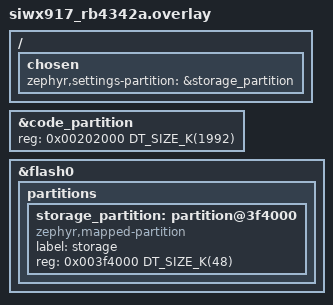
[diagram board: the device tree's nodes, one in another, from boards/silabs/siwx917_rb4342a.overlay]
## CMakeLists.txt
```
#
#    Copyright (c) 2026 Project CHIP Authors
#
#    Licensed under the Apache License, Version 2.0 (the "License");
#    you may not use this file except in compliance with the License.
#    You may obtain a copy of the License at
#
#        http://www.apache.org/licenses/LICENSE-2.0
#
#    Unless required by applicable law or agreed to in writing, software
#    distributed under the License is distributed on an "AS IS" BASIS,
#    WITHOUT WARRANTIES OR CONDITIONS OF ANY KIND, either express or implied.
#    See the License for the specific language governing permissions and
#    limitations under the License.
#
cmake_minimum_required(VERSION 3.20)

# You may point this at a header that defines chip::app::AllDevices::AppTask as the
# final type of a CRTP layer chain rooted at AppTaskBase (see include/AppTask.h).
if(NOT DEFINED APP_TASK_IMPL_HEADER)
    set(APP_TASK_IMPL_HEADER "")
endif()

# Zephyr auto-discovers files directly under boards/. This also discovers
# board files in the registered vendor subdirectories.
include(${CMAKE_CURRENT_SOURCE_DIR}/cmake/board_files.cmake)
if(DEFINED BOARD)
    all_devices_board_name(${BOARD} ALL_DEVICES_BOARD_NAME)

    if(NOT SYSBUILD)
        all_devices_find_board_file(${CMAKE_CURRENT_SOURCE_DIR}/boards ${ALL_DEVICES_BOARD_NAME}.overlay
                                     ALL_DEVICES_NESTED_BOARD_OVERLAY EXCLUDE_FLAT)
        if(ALL_DEVICES_NESTED_BOARD_OVERLAY)
            list(APPEND DTC_OVERLAY_FILE ${ALL_DEVICES_NESTED_BOARD_OVERLAY})
            set(DTC_OVERLAY_FILE "${DTC_OVERLAY_FILE}" CACHE STRING "Application devicetree overlays" FORCE)
        endif()
    else()
        all_devices_find_board_file(${CMAKE_CURRENT_SOURCE_DIR}/boards ${ALL_DEVICES_BOARD_NAME}.overlay
                                     ALL_DEVICES_NESTED_BOARD_OVERLAY EXCLUDE_FLAT)
        list(REMOVE_ITEM DTC_OVERLAY_FILE ${ALL_DEVICES_NESTED_BOARD_OVERLAY})
        set(DTC_OVERLAY_FILE "${DTC_OVERLAY_FILE}" CACHE STRING "Application devicetree overlays" FORCE)
    endif()
    message(VERBOSE "BOARD=${BOARD} ALL_DEVICES_BOARD_NAME=${ALL_DEVICES_BOARD_NAME} ALL_DEVICES_NESTED_BOARD_OVERLAY=${ALL_DEVICES_NESTED_BOARD_OVERLAY} EXTRA_DTC_OVERLAY_FILE=${EXTRA_DTC_OVERLAY_FILE}")

    all_devices_find_board_file(${CMAKE_CURRENT_SOURCE_DIR}/boards ${ALL_DEVICES_BOARD_NAME}.conf
                                 ALL_DEVICES_NESTED_BOARD_CONF EXCLUDE_FLAT)
    if(ALL_DEVICES_NESTED_BOARD_CONF)
        list(APPEND EXTRA_CONF_FILE ${ALL_DEVICES_NESTED_BOARD_CONF})
    endif()

endif()

find_package(Zephyr HINTS $ENV{ZEPHYR_BASE})

# Matter is the Zephyr module "connectedhomeip"; it must be in the west manifest.
if(NOT DEFINED ZEPHYR_CONNECTEDHOMEIP_MODULE_DIR)
    message(FATAL_ERROR "Matter is not registered as a Zephyr module. Add it to your west manifest.")
endif()
set(CHIP_ROOT ${ZEPHYR_CONNECTEDHOMEIP_MODULE_DIR})
set(ALL_DEVICES_COMMON_DIR ${CHIP_ROOT}/examples/all-devices-app/all-devices-common)

# Device selection comes from Kconfig (CONFIG_ALL_DEVICES_DEVICE_*, see Kconfig.devices).
# -DALL_DEVICES_ENABLED_DEVICES="on-off-light;..." overrides it; an empty list means all devices.
if(NOT DEFINED ALL_DEVICES_ENABLED_DEVICES)
    set(ALL_DEVICES_ENABLED_DEVICES "")
    get_cmake_property(_all_devices_vars VARIABLES)
    foreach(_var IN LISTS _all_devices_vars)
        if(_var MATCHES "^CONFIG_ALL_DEVICES_DEVICE_(.+)$" AND ${_var})
            string(TOLOWER "${CMAKE_MATCH_1}" _key)
            string(REPLACE "_" "-" _key "${_key}")
            list(APPEND ALL_DEVICES_ENABLED_DEVICES "${_key}")
        endif()
    endforeach()
endif()
include(${ALL_DEVICES_COMMON_DIR}/device-factory/enabled_devices.cmake)

# Count enabled device keys to size AppTask's device array. 
get_cmake_property(_all_devices_vars VARIABLES)
set(ALL_DEVICES_ENABLED_DEVICE_COUNT 0)
foreach(_var IN LISTS _all_devices_vars)
    if(_var MATCHES "^ALL_DEVICES_ENABLE_" AND ${_var})
        math(EXPR ALL_DEVICES_ENABLED_DEVICE_COUNT "${ALL_DEVICES_ENABLED_DEVICE_COUNT} + 1")
    endif()
endforeach()

#Some keys register more than one creator, so include those additional creators as well.
foreach(_variant_key FAN OVEN REFRIGERATOR)
    if(ALL_DEVICES_ENABLE_${_variant_key})
        math(EXPR ALL_DEVICES_ENABLED_DEVICE_COUNT "${ALL_DEVICES_ENABLED_DEVICE_COUNT} + 1")
    endif()
endforeach()

# ot-config re-lists zephyr_interface's INTERFACE_COMPILE_DEFINITIONS, including
# $<COMPILE_LANGUAGE:CXX> generator expressions. openthread/CMakeLists.txt uses
# ot-config's defines to build a plain custom target, where COMPILE_LANGUAGE is
# invalid. Strip it so LLVM/Clang builds configure cleanly.
if(CONFIG_OPENTHREAD AND TARGET ot-config AND TARGET zephyr_interface)
    get_target_property(OT_CONFIG_DEFS ot-config INTERFACE_COMPILE_DEFINITIONS)
    if(OT_CONFIG_DEFS)
        list(FILTER OT_CONFIG_DEFS EXCLUDE REGEX "TARGET_PROPERTY:zephyr_interface,INTERFACE_COMPILE_DEFINITIONS")
    else()
        set(OT_CONFIG_DEFS "")
    endif()
    get_target_property(ZEPHYR_INTERFACE_DEFS zephyr_interface INTERFACE_COMPILE_DEFINITIONS)
    if(ZEPHYR_INTERFACE_DEFS)
        list(FILTER ZEPHYR_INTERFACE_DEFS EXCLUDE REGEX "COMPILE_LANGUAGE:CXX")
    else()
        set(ZEPHYR_INTERFACE_DEFS "")
    endif()
    set_target_properties(ot-config PROPERTIES
        INTERFACE_COMPILE_DEFINITIONS "${OT_CONFIG_DEFS};${ZEPHYR_INTERFACE_DEFS}")
endif()

project(matter-all-devices-zephyr)

include(${CHIP_ROOT}/src/app/chip_data_model.cmake)

# Silabs extension point
include(${CMAKE_CURRENT_SOURCE_DIR}/silabs/CMakeLists.txt)

target_compile_options(app PRIVATE -Werror -Wno-error=format)
if(CMAKE_C_COMPILER_ID STREQUAL "GNU")
    target_compile_options(app PRIVATE -Werror -Wno-error=maybe-uninitialized)
endif()

target_compile_definitions(app PRIVATE ALL_DEVICES_ENABLED_DEVICE_COUNT=${ALL_DEVICES_ENABLED_DEVICE_COUNT})

if(NOT APP_TASK_IMPL_HEADER STREQUAL "")
    target_compile_definitions(app PRIVATE APP_TASK_IMPL_HEADER="${APP_TASK_IMPL_HEADER}")
endif()

target_include_directories(app PRIVATE
    ${CMAKE_CURRENT_SOURCE_DIR}
    src
    include
    ${ALL_DEVICES_COMMON_DIR}
    ${CMAKE_CURRENT_BINARY_DIR} # for generated app_config/enabled_devices.h
)

target_sources(app PRIVATE
    CHIPProjectConfig.h
    include/AppTaskBase.h
    include/AppTaskBase.ipp
    include/AppTask.h
    include/Buttons.h
    src/Buttons.cpp
    src/main.cpp

    # Identify
    include/delegates/ZephyrIdentifyDelegate.h
    src/delegates/ZephyrIdentifyDelegate.cpp

    # all-devices-common
    ${ALL_DEVICES_DEVICE_SOURCES}
    ${ALL_DEVICES_CLUSTER_SOURCES}
)

# Included by AppTaskBase.h; listed above only so it shows up in IDEs.
set_source_files_properties(include/AppTaskBase.ipp PROPERTIES HEADER_FILE_ONLY TRUE)

# Board-specific device implementation; AppTaskBase substitutes it into the factory.
if(ALL_DEVICES_ENABLE_ON_OFF_LIGHT)
    target_sources(app PRIVATE
        include/devices/ZephyrOnOffLight.h
        src/devices/ZephyrOnOffLight.cpp
    )
endif()

# Matches CHIP_DEVICE_CONFIG_ENABLE_THREAD, which AppTaskBase.ipp gates on.
if(CONFIG_OPENTHREAD)
    target_sources(app PRIVATE
        ${ALL_DEVICES_COMMON_DIR}/device/types/root-node/features/ThreadFeature.cpp
        )
endif()

if(CONFIG_CHIP_WIFI)
    target_sources(app PRIVATE
        ${ALL_DEVICES_COMMON_DIR}/device/types/root-node/features/WifiFeature.cpp
    )
endif()

if(CONFIG_CHIP_OTA_REQUESTOR)
    target_sources(app PRIVATE
        ${ALL_DEVICES_COMMON_DIR}/device/types/root-node/features/OtaFeature.cpp
        ${CHIP_ROOT}/src/app/clusters/ota-requestor/BDXDownloader.cpp
        ${CHIP_ROOT}/src/app/clusters/ota-requestor/DefaultOTARequestor.cpp
        ${CHIP_ROOT}/src/app/clusters/ota-requestor/DefaultOTARequestorDriver.cpp
        ${CHIP_ROOT}/src/app/clusters/ota-requestor/DefaultOTARequestorStorage.cpp
        ${CHIP_ROOT}/src/app/clusters/ota-requestor/ExtendedOTARequestorDriver.cpp
        ${CHIP_ROOT}/src/app/clusters/ota-requestor/OTATestEventTriggerHandler.cpp
        ${CHIP_ROOT}/src/app/clusters/ota-requestor/OTARequestorAttributes.cpp
        ${CHIP_ROOT}/src/app/clusters/ota-requestor/OTARequestorCluster.cpp
    )

    if(CONFIG_MCUBOOT_SIGNATURE_KEY_FILE STREQUAL "")
        set(ALL_DEVICES_OTA_BASE_NAME "zephyr")
    else()
        set(ALL_DEVICES_OTA_BASE_NAME "zephyr.signed")
    endif()

    if(CONFIG_CHIP_OTA_IMAGE_BUILD)
        chip_zephyr_ota_image(chip-ota-image
            INPUT_FILES ${PROJECT_BINARY_DIR}/zephyr/${ALL_DEVICES_OTA_BASE_NAME}.bin
            OUTPUT_FILE ${PROJECT_BINARY_DIR}/zephyr/${CONFIG_CHIP_OTA_IMAGE_FILE_NAME}
        )
    endif()
endif()
```

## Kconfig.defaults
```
#
# Copyright (c) 2026 Project CHIP Authors
#
# Licensed under the Apache License, Version 2.0 (the "License");
# you may not use this file except in compliance with the License.
# You may obtain a copy of the License at
#
# http://www.apache.org/licenses/LICENSE-2.0
#
# Unless required by applicable law or agreed to in writing, software
# distributed under the License is distributed on an "AS IS" BASIS,
# WITHOUT WARRANTIES OR CONDITIONS OF ANY KIND, either express or implied.
# See the License for the specific language governing permissions and
# limitations under the License.
#

DT_CHOSEN_IEEE802154 := zephyr,ieee802154

if CHIP

# Only enable the OpenThread L2 on boards that expose a 802.15.4 radio.
config NET_L2_OPENTHREAD
	default y if $(dt_chosen_enabled,$(DT_CHOSEN_IEEE802154))
	default n

choice STD_CPP
	default STD_CPP17
endchoice

config CHIP_ENABLE_PAIRING_AUTOSTART
	default y

# The app builds its data model at run time.
config CHIP_DATA_MODEL_CODEDRIVEN
	default y

config CHIP_ENABLE_GROUPCAST
	default y

config CHIP_PERSISTENT_SUBSCRIPTIONS
	default y

config CHIP_OTA_REQUESTOR
	default n

config IMG_MANAGER
	default y if CHIP_OTA_BACKEND_MCUBOOT

config STREAM_FLASH
	default n

config STREAM_FLASH_ERASE
	default n

config BOOTLOADER_MCUBOOT
	default y if CHIP_OTA_BACKEND_MCUBOOT

config CHIP_OTA_BACKEND_MCUBOOT
	imply STREAM_FLASH
	imply STREAM_FLASH_ERASE

config BT
	default y

config BT_PERIPHERAL
	default y

config BT_DEVICE_NAME
	default "MatterAllDev"

config BT_HOST_CRYPTO
	default y

config MBEDTLS_ENTROPY_C
	default y

config MBEDTLS_PSA_DRIVER_GET_ENTROPY
	default y

config LOG
	default y

choice LOG_MODE
	default LOG_MODE_DEFERRED
endchoice

config SYSTEM_WORKQUEUE_STACK_SIZE
	default 4096

config THREAD_LOCAL_STORAGE
	default y

config MAIN_STACK_SIZE
	default 12288

config CHIP_TASK_STACK_SIZE
	default 10240

config HW_STACK_PROTECTION
	default y

config ASSERT
	default y

if NET_L2_OPENTHREAD

config NET_IF_MCAST_IPV6_ADDR_COUNT
	default 14

config OPENTHREAD_THREAD_STACK_SIZE
	default 6144

endif # NET_L2_OPENTHREAD

choice POSIX_AEP_CHOICE
	default POSIX_AEP_CHOICE_NONE
endchoice

config MBEDTLS
	default y

choice CHIP_CRYPTO
	default CHIP_CRYPTO_PSA
endchoice

config MBEDTLS_HEAP_SIZE
	default 8192

# CHIPCryptoPALPSA.cpp uses mbedtls_md_info_from_type() for SPAKE2+.
config MBEDTLS_MD_C
	default y if CHIP_CRYPTO_SPAKE2P_MBEDTLS

# Extend the maximum number of PSA key slots to fit Matter requirements
config MBEDTLS_PSA_KEY_SLOT_COUNT
	default 64

config CHIP_FACTORY_DATA
	bool "Use provisioned factory data for credentials and commissionable data"
	default n

config SHELL
	default y

config CHIP_LIB_SHELL
	default y

config CHIP_WIFI
	default y if WIFI
	imply NET_STATISTICS
	imply NET_IPV6_ND
	imply NET_IPV6_NBR_CACHE
	imply NET_STATISTICS_IPV6
	imply NET_STATISTICS_USER_API

config CHIP_ENABLE_WIFI_STATION
	default y if CHIP_WIFI

if CHIP_WIFI
config NET_IF_IPV6_PREFIX_COUNT
	default NET_IF_UNICAST_IPV6_ADDR_COUNT
config NET_BUF_DATA_SIZE
	default 512
endif

if SHELL

config SHELL_STACK_SIZE
    default 2616 if CHIP_WIFI

config SHELL_MINIMAL
    default y

config KERNEL_SHELL
    default n

config SHELL_WILDCARD
	default n

config SENSOR_SHELL
    default n

config DEVICE_SHELL
    default n

config DATE_SHELL
    default n

config DEVMEM_SHELL
    default n

config MCUBOOT_SHELL
    default n

config CLOCK_CONTROL_NRF_SHELL
    default n

config FLASH_SHELL
    default n

config HWINFO_SHELL
    default n

endif # SHELL

# Silabs optimizations
if SOC_FAMILY_SILABS_S2 && $(dt_chosen_enabled,$(DT_CHOSEN_IEEE802154))

# OpenThread L2 still needs Zephyr networking without Matter socket endpoints.
config NETWORKING
	default y

config CHIP_USE_ZEPHYR_NETWORKING
	default n

if NET_L2_OPENTHREAD

config CHIP_USE_OT_ENDPOINT
	default !CHIP_USE_ZEPHYR_NETWORKING

config NET_IPV6_NBR_CACHE
	default n if CHIP_USE_OT_ENDPOINT

config NET_PKT_RX_COUNT
	default 8

config NET_PKT_TX_COUNT
	default 8

config NET_BUF_RX_COUNT
	default 16

config NET_BUF_TX_COUNT
	default 16

config OPENTHREAD_NUM_MESSAGE_BUFFERS
	default 64

if CHIP_CRYPTO_PSA

choice OPENTHREAD_SECURITY_CONFIG
	default OPENTHREAD_SECURITY_CUSTOM_CONFIG
endchoice

# Custom Thread security does not imply PSA persistent-key storage.
config SECURE_STORAGE
	default y if !BUILD_WITH_TFM

config PSA_WANT_KEY_TYPE_HMAC
	default y

config PSA_WANT_KEY_TYPE_ECC_KEY_PAIR_IMPORT
	default y

config PSA_WANT_KEY_TYPE_ECC_KEY_PAIR_EXPORT
	default y

config PSA_WANT_ALG_DETERMINISTIC_ECDSA
	default y

config MBEDTLS_ASN1_PARSE_C
	default y

config CHIP_CRYPTO_PSA_AEAD_SINGLE_PART
	default y

endif # CHIP_CRYPTO_PSA

if MCUBOOT_IMG_MANAGER

config IMG_ERASE_PROGRESSIVELY
	default y

endif # MCUBOOT_IMG_MANAGER

endif # NET_L2_OPENTHREAD

endif # SOC_FAMILY_SILABS_S2 && DT_CHOSEN_IEEE802154

endif # CHIP
```

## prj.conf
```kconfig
#
#    Copyright (c) 2026 Project CHIP Authors
#
#    Licensed under the Apache License, Version 2.0 (the "License");
#    you may not use this file except in compliance with the License.
#    You may obtain a copy of the License at
#
#        http://www.apache.org/licenses/LICENSE-2.0
#
#    Unless required by applicable law or agreed to in writing, software
#    distributed under the License is distributed on an "AS IS" BASIS,
#    WITHOUT WARRANTIES OR CONDITIONS OF ANY KIND, either express or implied.
#    See the License for the specific language governing permissions and
#    limitations under the License.
#

CONFIG_CHIP=y
CONFIG_LOG_DEFAULT_LEVEL=3
CONFIG_CHIP_PROJECT_CONFIG="CHIPProjectConfig.h"
CONFIG_OPENTHREAD_SHELL=n

CONFIG_BUILD_OUTPUT_HEX=y
CONFIG_LOG_BUFFER_SIZE=6144

CONFIG_BT_GATT_CACHING=n
```

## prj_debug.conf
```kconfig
#
#    Copyright (c) 2026 Project CHIP Authors
#
#    Licensed under the Apache License, Version 2.0 (the "License");
#    you may not use this file except in compliance with the License.
#    You may obtain a copy of the License at
#
#        http://www.apache.org/licenses/LICENSE-2.0
#
#    Unless required by applicable law or agreed to in writing, software
#    distributed under the License is distributed on an "AS IS" BASIS,
#    WITHOUT WARRANTIES OR CONDITIONS OF ANY KIND, either express or implied.
#    See the License for the specific language governing permissions and
#    limitations under the License.
#

# west build ... -- -DFILE_SUFFIX=debug

CONFIG_CHIP=y
CONFIG_CHIP_PROJECT_CONFIG="CHIPProjectConfig.h"

# Thread introspection: names threads and lists them via the "kernel threads"
# shell command.
CONFIG_THREAD_NAME=y
CONFIG_THREAD_MONITOR=y

# Zero-fills thread stacks at creation and checks a canary word on each
# context switch, so stack overflows/high-water-marks can be diagnosed.
CONFIG_INIT_STACKS=y
CONFIG_STACK_SENTINEL=y

# Verbose application + Matter stack logging.
CONFIG_LOG_DEFAULT_LEVEL=4
CONFIG_CHIP_APP_LOG_LEVEL=4
CONFIG_LOG_INFO_COLOR_GREEN=y
CONFIG_LOG_DBG_COLOR_BLUE=y

# OTA Requestor (MCUboot stream flash / image manager come from Kconfig.defaults)
CONFIG_CHIP_OTA_REQUESTOR=y

# Full __ASSERT() checking (adds spinlock validation and per-assert file info).
CONFIG_ASSERT=y
CONFIG_HW_STACK_PROTECTION=y

CONFIG_SHELL=y
CONFIG_CHIP_LIB_SHELL=y

CONFIG_CONSOLE=y
CONFIG_UART_CONSOLE=y
CONFIG_SERIAL=y
CONFIG_LOG=y
CONFIG_PRINTK=y
CONFIG_PRINTK_SYNC=n
CONFIG_BOOT_BANNER=y

CONFIG_BT_GATT_CACHING=n
```

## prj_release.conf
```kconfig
#
#    Copyright (c) 2026 Project CHIP Authors
#
#    Licensed under the Apache License, Version 2.0 (the "License");
#    you may not use this file except in compliance with the License.
#    You may obtain a copy of the License at
#
#        http://www.apache.org/licenses/LICENSE-2.0
#
#    Unless required by applicable law or agreed to in writing, software
#    distributed under the License is distributed on an "AS IS" BASIS,
#    WITHOUT WARRANTIES OR CONDITIONS OF ANY KIND, either express or implied.
#    See the License for the specific language governing permissions and
#    limitations under the License.
#

# west build ... -- -DFILE_SUFFIX=release

CONFIG_CHIP=y
CONFIG_CHIP_PROJECT_CONFIG="CHIPProjectConfig.h"

CONFIG_USE_SEGGER_RTT=n

# No shell (Matter or OT) in a release build.
CONFIG_SHELL=n
CONFIG_CHIP_LIB_SHELL=n

# No console/log output path at all.
CONFIG_CONSOLE=n
CONFIG_UART_CONSOLE=n
CONFIG_SERIAL=n
CONFIG_LOG=n
CONFIG_PRINTK=n
CONFIG_PRINTK_SYNC=n
CONFIG_BOOT_BANNER=n
CONFIG_MATTER_LOG_LEVEL=0
CONFIG_CHIP_APP_LOG_LEVEL=0

# Development aids
CONFIG_ASSERT=n

# Use Factory Data
# Requires providing a custom implementation
CONFIG_CHIP_FACTORY_DATA=y

# OTA
CONFIG_CHIP_OTA_REQUESTOR=y
CONFIG_CHIP_OTA_IMAGE_BUILD=y
CONFIG_CHIP_DEVICE_SOFTWARE_VERSION=1
CONFIG_CHIP_DEVICE_SOFTWARE_VERSION_STRING="1.0"
CONFIG_MCUBOOT_IMGTOOL_SIGN_VERSION="1.0.0+0"

# LTO
CONFIG_ISR_TABLES_LOCAL_DECLARATION=y
CONFIG_LTO=y
CONFIG_LTO_SINGLE_THREADED=y

CONFIG_BT_GATT_CACHING=n

CONFIG_CBPRINTF_FP_SUPPORT=n
```

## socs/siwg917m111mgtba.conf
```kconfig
#
#    Copyright (c) 2026 Project CHIP Authors
#    All rights reserved.
#
#    Licensed under the Apache License, Version 2.0 (the "License");
#    you may not use this file except in compliance with the License.
#    You may obtain a copy of the License at
#
#        http://www.apache.org/licenses/LICENSE-2.0
#
#    Unless required by applicable law or agreed to in writing, software
#    distributed under the License is distributed on an "AS IS" BASIS,
#    WITHOUT WARRANTIES OR CONDITIONS OF ANY KIND, either express or implied.
#    See the License for the specific language governing permissions and
#    limitations under the License.
#

CONFIG_NVS_LOOKUP_CACHE=y
CONFIG_NVS_LOOKUP_CACHE_SIZE=1024

CONFIG_SETTINGS_NVS_SECTOR_COUNT=12

# Si917 Wi-Fi / Matter-over-Wi-Fi integration.  Keep these explicit instead of
# relying solely on the generic defaults in Kconfig.defaults: CONFIG_WIFI makes
# CHIP_WIFI available, and the latter two select the Matter Wi-Fi root feature
# (Network Commissioning + Wi-Fi Network Diagnostics) and station driver.
CONFIG_WIFI=y
CONFIG_CHIP_WIFI=y
CONFIG_CHIP_ENABLE_WIFI_STATION=y
CONFIG_COMMON_LIBC_MALLOC_ARENA_SIZE=-1

CONFIG_GPIO=y

CONFIG_NET_IF_UNICAST_IPV6_ADDR_COUNT=6
CONFIG_NET_IF_MCAST_IPV6_ADDR_COUNT=14

CONFIG_LOG_BUFFER_SIZE=8192

CONFIG_MBEDTLS_ECP_NIST_OPTIM=y
```

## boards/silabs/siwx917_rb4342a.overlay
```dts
/*
 * Copyright (c) 2026 Project CHIP Authors
 *
 * Licensed under the Apache License, Version 2.0 (the "License");
 * you may not use this file except in compliance with the License.
 * You may obtain a copy of the License at
 *
 *     http://www.apache.org/licenses/LICENSE-2.0
 *
 * Unless required by applicable law or agreed to in writing, software
 * distributed under the License is distributed on an "AS IS" BASIS
 * WITHOUT WARRANTIES OR CONDITIONS OF ANY KIND, either express or implied.
 * See the License for the specific language governing permissions and
 * limitations under the License.
 */

/delete-node/ &storage_partition;

/ {
	chosen {
		zephyr,settings-partition = &storage_partition;
	};
};

&code_partition {
	reg = <0x00202000 DT_SIZE_K(1992)>;
};

&flash0 {
	partitions {
		storage_partition: partition@3f4000 {
			compatible = "zephyr,mapped-partition";
			label = "storage";
			reg = <0x003f4000 DT_SIZE_K(48)>;
		};
	};
};
```

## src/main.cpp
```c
/*
 *
 *    Copyright (c) 2026 Project CHIP Authors
 *    All rights reserved.
 *
 *    Licensed under the Apache License, Version 2.0 (the "License");
 *    you may not use this file except in compliance with the License.
 *    You may obtain a copy of the License at
 *
 *        http://www.apache.org/licenses/LICENSE-2.0
 *
 *    Unless required by applicable law or agreed to in writing, software
 *    distributed under the License is distributed on an "AS IS" BASIS,
 *    WITHOUT WARRANTIES OR CONDITIONS OF ANY KIND, either express or implied.
 *    See the License for the specific language governing permissions and
 *    limitations under the License.
 */

#include "AppTask.h"

#include <lib/core/CHIPError.h>
#include <zephyr/kernel.h>

void RegisterNamedPipeTranslators(DimmableLight & device, NamedPipe::Dispatcher & dispatcher)
{
    const CHIP_ERROR err = chip::app::AllDevices::GetAppTask().Run();
    if (err != CHIP_NO_ERROR)
    {
        printk("AppTask::Run() failed: %" CHIP_ERROR_FORMAT "\n", err.Format());
        return EXIT_FAILURE;
    }

    return EXIT_SUCCESS;
}
```

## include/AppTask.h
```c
/*
 *    Copyright (c) 2026 Project CHIP Authors
 *    All rights reserved.
 *
 *    Licensed under the Apache License, Version 2.0 (the "License");
 *    you may not use this file except in compliance with the License.
 *    You may obtain a copy of the License at
 *
 *        http://www.apache.org/licenses/LICENSE-2.0
 *
 *    Unless required by applicable law or agreed to in writing, software
 *    distributed under the License is distributed on an "AS IS" BASIS,
 *    WITHOUT WARRANTIES OR CONDITIONS OF ANY KIND, either express or implied.
 *    See the License for the specific language governing permissions and
 *    limitations under the License.
 */

#pragma once

#include "AppTaskBase.h"

#ifdef APP_TASK_IMPL_HEADER
#include APP_TASK_IMPL_HEADER
#else

namespace chip::app::AllDevices {

class AppTask final : public AppTaskBase<AppTask>
{
};

} // namespace chip::app::AllDevices

#endif // APP_TASK_IMPL_HEADER

namespace chip::app::AllDevices {

inline AppTask gAppTask;

inline AppTask & GetAppTask()
{
    return gAppTask;
}

} // namespace chip::app::AllDevices
```

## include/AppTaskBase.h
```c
/*
 *
 *    Copyright (c) 2026 Project CHIP Authors
 *    All rights reserved.
 *
 *    Licensed under the Apache License, Version 2.0 (the "License");
 *    you may not use this file except in compliance with the License.
 *    You may obtain a copy of the License at
 *
 *        http://www.apache.org/licenses/LICENSE-2.0
 *
 *    Unless required by applicable law or agreed to in writing, software
 *    distributed under the License is distributed on an "AS IS" BASIS,
 *    WITHOUT WARRANTIES OR CONDITIONS OF ANY KIND, either express or implied.
 *    See the License for the specific language governing permissions and
 *    limitations under the License.
 */

#pragma once

#include <app/DefaultSafeAttributePersistenceProvider.h>
#include <app/persistence/DefaultAttributePersistenceProvider.h>
#include <app/server/Server.h>
#include <credentials/GroupDataProviderImpl.h>
#include <data-model-providers/codedriven/CodeDrivenDataModelProvider.h>
#include <device/api/Interface.h>
#include <lib/core/CHIPError.h>
#include <platform/CHIPDeviceEvent.h>
#include <platform/DefaultTimerDelegate.h>
#if CHIP_DEVICE_CONFIG_ENABLE_THREAD
#include <platform/OpenThread/GenericNetworkCommissioningThreadDriver.h>
#endif // CHIP_DEVICE_CONFIG_ENABLE_THREAD

#include "delegates/ZephyrIdentifyDelegate.h"

#if CHIP_DEVICE_CONFIG_ENABLE_WIFI
#include <platform/Zephyr/wifi/ZephyrWifiDriver.h>
#endif // CHIP_DEVICE_CONFIG_ENABLE_WIFI

#if CHIP_DEVICE_CONFIG_ENABLE_OTA_REQUESTOR
#include <app/clusters/ota-requestor/BDXDownloader.h>
#include <app/clusters/ota-requestor/DefaultOTARequestor.h>
#include <app/clusters/ota-requestor/DefaultOTARequestorDriver.h>
#include <app/clusters/ota-requestor/DefaultOTARequestorStorage.h>
#include <app/clusters/ota-requestor/OTARequestorAttributes.h>
#include <device/types/root-node/features/OtaFeature.h>
#endif // CHIP_DEVICE_CONFIG_ENABLE_OTA_REQUESTOR

#include <memory>

namespace chip::app::AllDevices {

/**
 * Generic Zephyr Matter application task.
 *
 * This is a CRTP base. `Derived` is the final application type. `Run()` sets the
 * order of the initialization steps and calls each step through `Self()`. To
 * replace a step, declare a step with the same name in a derived class.
 *
 * Make your custom layer a template. Then you can stack the layers:
 *
 *     template <class D> class CustomAppTask : public AppTaskBase<D> { ... };
 *     class AppTask final : public CustomAppTask<AppTask> {};
 *
 * To also run the generic behaviour, call `AppTaskBase<D>::Step()` from your step.
 */
template <class Derived>
class AppTaskBase
{
public:
    /// Runs every initialization step in order, then starts the CHIP event
    /// loop. Returns on the first failure.
    CHIP_ERROR Run();

    CHIP_ERROR InitPlatform();

    // SetDeviceAttestationCredentialsProvider and SetDeviceInstanceInfoProvider
    CHIP_ERROR InitCredentials();

    // Dispatches to InitThreadNetworking() / InitWifiNetworking().
    CHIP_ERROR InitNetwork();

    CHIP_ERROR InitThreadNetworking();

    // Binds the Zephyr Wi-Fi station driver to the optional Matter shell. The
    // driver itself is consumed by WifiFeature when it creates the root
    // Network Commissioning and Wi-Fi Network Diagnostics clusters.
    CHIP_ERROR InitWifiNetworking();

    /// Storage/group data provider setup.
    CHIP_ERROR InitPersistence();

    TestEventTriggerDelegate & GetTestEventTriggerDelegate();

    /// Identify delegate handed to every device created by the DeviceFactory.
    Clusters::IdentifyDelegate & GetIdentifyDelegate();

    CHIP_ERROR InitRootNode();

    /// Substitutes board-specific implementations
    CHIP_ERROR RegisterDeviceCreators();

    /// Instantiates every type in DeviceFactory::SupportedDeviceTypes().
    CHIP_ERROR RegisterAppDevices();

    CHIP_ERROR InitServer();

    // Factory reset button
    CHIP_ERROR InitBoardControls();

    CHIP_ERROR PostServerInit();

    /// Called inside OnPlatformEvent when server is ready.
    CHIP_ERROR InitOTARequestor();

protected:
    static constexpr EndpointId kRootEndpointId        = 0;
    static constexpr EndpointId kFirstDeviceEndpointId = 1;

    Derived & Self() { return static_cast<Derived &>(*this); }

    static void OnPlatformEvent(const DeviceLayer::ChipDeviceEvent * event, intptr_t context);

    chip::CommonCaseDeviceServerInitParams mInitParams;
    Credentials::GroupDataProviderImpl mGroupDataProvider;
    SimpleTestEventTriggerDelegate mDefaultTestEventTriggerDelegate;
    ZephyrIdentifyDelegate mDefaultIdentifyDelegate;
    DefaultTimerDelegate mTimerDelegate;
    DefaultAttributePersistenceProvider mAttributePersistenceProvider;
    DefaultSafeAttributePersistenceProvider mSafeAttributePersistenceProvider;

#if CHIP_DEVICE_CONFIG_ENABLE_THREAD
    DeviceLayer::NetworkCommissioning::GenericThreadDriver mThreadDriver;
#endif // CHIP_DEVICE_CONFIG_ENABLE_THREAD

#if CHIP_DEVICE_CONFIG_ENABLE_WIFI
    // Must be the singleton: WiFiManager completion callbacks call ZephyrWifiDriver::Instance().
    DeviceLayer::NetworkCommissioning::ZephyrWifiDriver & mWifiDriver =
        DeviceLayer::NetworkCommissioning::ZephyrWifiDriver::Instance();
#endif // CHIP_DEVICE_CONFIG_ENABLE_WIFI

    std::unique_ptr<CodeDrivenDataModelProvider> mDataModelProvider;
    std::unique_ptr<DeviceInterface> mRootNode;

    std::unique_ptr<DeviceInterface> mDevices[ALL_DEVICES_ENABLED_DEVICE_COUNT];
    size_t mDeviceCount = 0;

#if CHIP_DEVICE_CONFIG_ENABLE_OTA_REQUESTOR
    chip::DefaultOTARequestor mOTARequestorCore;
    chip::DefaultOTARequestorStorage mOTARequestorStorage;
    DeviceLayer::DefaultOTARequestorDriver mOTARequestorDriver;
    chip::BDXDownloader mOTADownloader;
    chip::OTARequestorAttributes mOTARequestorAttributes;
    LazyRegisteredServerCluster<Clusters::OTARequestorCluster> mOTARequestorCluster;
#endif // CHIP_DEVICE_CONFIG_ENABLE_OTA_REQUESTOR
};

} // namespace chip::app::AllDevices

#include "AppTaskBase.ipp"
```

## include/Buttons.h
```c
/*
 *
 *    Copyright (c) 2026 Project CHIP Authors
 *    All rights reserved.
 *
 *    Licensed under the Apache License, Version 2.0 (the "License");
 *    you may not use this file except in compliance with the License.
 *    You may obtain a copy of the License at
 *
 *        http://www.apache.org/licenses/LICENSE-2.0
 *
 *    Unless required by applicable law or agreed to in writing, software
 *    distributed under the License is distributed on an "AS IS" BASIS,
 *    WITHOUT WARRANTIES OR CONDITIONS OF ANY KIND, either express or implied.
 *    See the License for the specific language governing permissions and
 *    limitations under the License.
 */

#pragma once

#include <device/capabilities/color-light/impl/LoggingLightDriver.h>
#include <device/types/extended-color-light/ExtendedColorLight.h>

#if DT_NODE_EXISTS(DT_ALIAS(sw0))
#define ALL_DEVICES_FACTORY_RESET_SW_NODE DT_ALIAS(sw0)
#endif

/**
 * Extended Color Light (device type 0x010D) whose output side only logs, so the device can be
 * exercised without anything behind it.
 */
class LoggingExtendedColorLight : private LoggingLightDriver, public ExtendedColorLight
{
public:
    explicit LoggingExtendedColorLight(const Context & context);
    ~LoggingExtendedColorLight() override = default;
};

namespace chip::app::AllDevices::Button {

/// Configures the factory-reset button when it exists.
CHIP_ERROR Init();

} // namespace chip::app::AllDevices::Button
```
